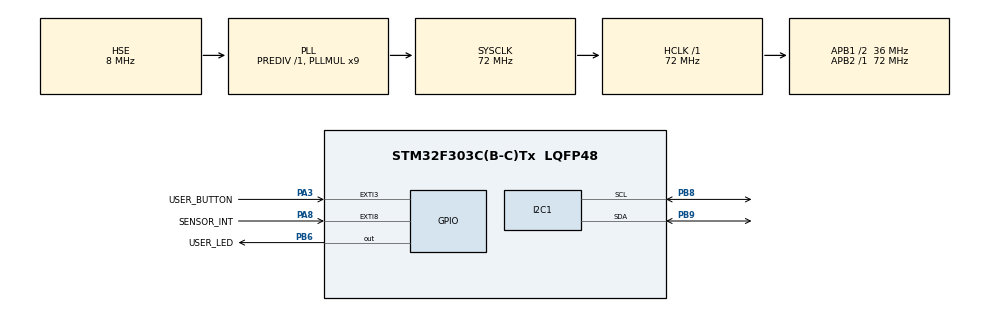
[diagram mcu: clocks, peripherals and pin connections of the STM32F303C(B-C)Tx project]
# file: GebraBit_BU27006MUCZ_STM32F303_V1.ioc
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I2C1.Timing=0x10808DD3
Mcu.Family=STM32F3
Mcu.Name=STM32F303C(B-C)Tx
Mcu.Package=LQFP48
NVIC.EXTI3_IRQn=true\:0\:0\:false\:false\:true\:true\:true\:true
NVIC.EXTI9_5_IRQn=true\:0\:0\:false\:false\:true\:true\:true\:true
NVIC.PriorityGroup=NVIC_PRIORITYGROUP_4
PA13.Mode=Serial_Wire
PA13.Signal=SYS_JTMS-SWDIO
PA14.Mode=Serial_Wire
PA14.Signal=SYS_JTCK-SWCLK
PA3.GPIO_Label=USER_BUTTON
PA3.GPIO_ModeDefaultEXTI=GPIO_MODE_IT_FALLING
PA3.Signal=GPXTI3
PA8.GPIO_Label=SENSOR_INT
PA8.GPIO_ModeDefaultEXTI=GPIO_MODE_IT_FALLING
PA8.Signal=GPXTI8
PB6.GPIO_Label=USER_LED
PB6.GPIO_Speed=GPIO_SPEED_FREQ_MEDIUM
PB6.PinState=GPIO_PIN_SET
PB6.Signal=GPIO_Output
PB8.Mode=I2C
PB8.Signal=I2C1_SCL
PB9.Mode=I2C
PB9.Signal=I2C1_SDA
PC14-OSC32_IN.Mode=LSE-External-Oscillator
PC14-OSC32_IN.Signal=RCC_OSC32_IN
PC15-OSC32_OUT.Mode=LSE-External-Oscillator
PC15-OSC32_OUT.Signal=RCC_OSC32_OUT
PF0-OSC_IN.Mode=HSE-External-Oscillator
PF0-OSC_IN.Signal=RCC_OSC_IN
PF1-OSC_OUT.Mode=HSE-External-Oscillator
PF1-OSC_OUT.Signal=RCC_OSC_OUT
ProjectManager.HeapSize=0x200
ProjectManager.StackSize=0x400
ProjectManager.TargetToolchain=MDK-ARM V5.32
RCC.AHBFreq_Value=72000000
RCC.APB1CLKDivider=RCC_HCLK_DIV2
RCC.APB1Freq_Value=36000000
RCC.APB1TimFreq_Value=72000000
RCC.APB2Freq_Value=72000000
RCC.APB2TimFreq_Value=72000000
RCC.CortexFreq_Value=72000000
RCC.HCLKFreq_Value=72000000
RCC.HSE_VALUE=8000000
RCC.HSI_VALUE=8000000
RCC.I2c1ClockSelection=RCC_I2C1CLKSOURCE_SYSCLK
RCC.PLLMUL=RCC_PLL_MUL9
RCC.PLLSourceVirtual=RCC_PLLSOURCE_HSE
RCC.SYSCLKFreq_VALUE=72000000
RCC.SYSCLKSourceVirtual=RCC_SYSCLKSOURCE_PLLCLK
RCC.USBFreq_Value=72000000
board=custom

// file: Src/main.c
/* USER CODE BEGIN Header */
/*
 * ________________________________________________________________________________________________________
 * Copyright (c) 2020 GebraBit Inc. All rights reserved.
 *
 * This software, related documentation and any modifications thereto (collectively “Software”) is subject
 * to GebraBit and its licensors' intellectual property rights under U.S. and international copyright
 * and other intellectual property rights laws.
 *
 * GebraBit and its licensors retain all intellectual property and proprietary rights in and to the Software
 * and any use, reproduction, disclosure or distribution of the Software without an express license agreement
 * from GebraBit is strictly prohibited.

 * THE SOFTWARE IS PROVIDED "AS IS", WITHOUT WARRANTY OF ANY KIND, EXPRESS OR IMPLIED, INCLUDING BUT
 * NOT LIMITED TO THE WARRANTIES OF MERCHANTABILITY, FITNESS FOR A PARTICULAR PURPOSE AND NON-INFRINGEMENT IN
 * NO EVENT SHALL GebraBit BE LIABLE FOR ANY DIRECT, SPECIAL, INDIRECT, INCIDENTAL, OR CONSEQUENTIAL DAMAGES,
 * OR ANY DAMAGES WHATSOEVER RESULTING FROM LOSS OF USE, DATA OR PROFITS, WHETHER IN AN ACTION OF CONTRACT,
 * NEGLIGENCE OR OTHER TORTIOUS ACTION, ARISING OUT OF OR IN CONNECTION WITH THE USE OR PERFORMANCE
 * OF THE SOFTWARE.
 * ________________________________________________________________________________________________________
 */
/**
  ******************************************************************************
  * @file           : main.c
  * @brief          : Main program body
	* @Author       	: Mehrdad Zeinali
  ******************************************************************************
  * @attention
  *
  * Copyright (c) 2022 STMicroelectronics.
  * All rights reserved.
  *
  * This software is licensed under terms that can be found in the LICENSE file
  * in the root directory of this software component.
  * If no LICENSE file comes with this software, it is provided AS-IS.
  *
  ******************************************************************************
  */
/* USER CODE END Header */
#include "main.h"
#include "i2c.h"
#include "gpio.h"

/* USER CODE BEGIN Includes */
#include "GebraBit_BU27006MUCZ.h"
/* USER CODE END Includes */

/* USER CODE BEGIN PTD */
GebraBit_BU27006MUCZ BU27006MUCZ_Module;
/* USER CODE END PTD */

void SystemClock_Config(void);

int main(void)
{

  /* MCU Configuration--------------------------------------------------------*/

  /* Reset of all peripherals, Initializes the Flash interface and the Systick. */
  HAL_Init();

  /* Configure the system clock */
  SystemClock_Config();

  /* Initialize all configured peripherals */
  MX_GPIO_Init();
  MX_I2C1_Init();
  /* USER CODE BEGIN 2 */
  GB_BU27006MUCZ_initialize(&BU27006MUCZ_Module);
	GB_BU27006MUCZ_Configuration(&BU27006MUCZ_Module);
  /* USER CODE END 2 */

  /* Infinite loop */
	while (1)
  {

    /* USER CODE BEGIN 3 */
		//GB_BU27006MUCZ_Get_Data(&BU27006MUCZ_Module);
		GB_BU27006MUCZ_Read_FIFO_Flicker_Data(&BU27006MUCZ_Module);
  }
  /* USER CODE END 3 */
}

void SystemClock_Config(void)
{
  RCC_OscInitTypeDef RCC_OscInitStruct = {0};
  RCC_ClkInitTypeDef RCC_ClkInitStruct = {0};
  RCC_PeriphCLKInitTypeDef PeriphClkInit = {0};

  /** Initializes the RCC Oscillators according to the specified parameters
  * in the RCC_OscInitTypeDef structure.
  */
  RCC_OscInitStruct.OscillatorType = RCC_OSCILLATORTYPE_HSE;
  RCC_OscInitStruct.HSEState = RCC_HSE_ON;
  RCC_OscInitStruct.HSEPredivValue = RCC_HSE_PREDIV_DIV1;
  RCC_OscInitStruct.HSIState = RCC_HSI_ON;
  RCC_OscInitStruct.PLL.PLLState = RCC_PLL_ON;
  RCC_OscInitStruct.PLL.PLLSource = RCC_PLLSOURCE_HSE;
  RCC_OscInitStruct.PLL.PLLMUL = RCC_PLL_MUL9;
  if (HAL_RCC_OscConfig(&RCC_OscInitStruct) != HAL_OK)
  {
    Error_Handler();
  }

  /** Initializes the CPU, AHB and APB buses clocks
  */
  RCC_ClkInitStruct.ClockType = RCC_CLOCKTYPE_HCLK|RCC_CLOCKTYPE_SYSCLK
                              |RCC_CLOCKTYPE_PCLK1|RCC_CLOCKTYPE_PCLK2;
  RCC_ClkInitStruct.SYSCLKSource = RCC_SYSCLKSOURCE_PLLCLK;
  RCC_ClkInitStruct.AHBCLKDivider = RCC_SYSCLK_DIV1;
  RCC_ClkInitStruct.APB1CLKDivider = RCC_HCLK_DIV2;
  RCC_ClkInitStruct.APB2CLKDivider = RCC_HCLK_DIV1;

  if (HAL_RCC_ClockConfig(&RCC_ClkInitStruct, FLASH_LATENCY_2) != HAL_OK)
  {
    Error_Handler();
  }
  PeriphClkInit.PeriphClockSelection = RCC_PERIPHCLK_I2C1;
  PeriphClkInit.I2c1ClockSelection = RCC_I2C1CLKSOURCE_SYSCLK;
  if (HAL_RCCEx_PeriphCLKConfig(&PeriphClkInit) != HAL_OK)
  {
    Error_Handler();
  }
}

void Error_Handler(void)
{
  __disable_irq();
  while (1)
  {
  }
}
